VERSION ""

NS_ :

BS_:

BU_: IVS

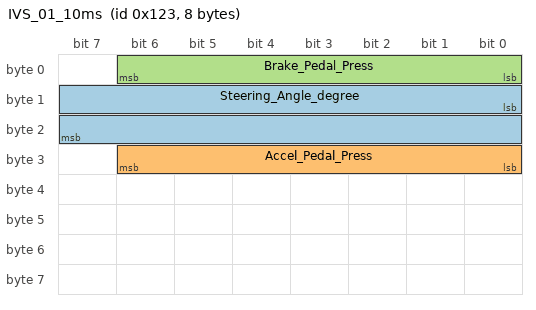
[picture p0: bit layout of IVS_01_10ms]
BO_ 291 IVS_01_10ms: 8 IVS
 SG_ Steering_Angle_degree : 8|16@1- (0.1,0) [0|0] "Deg" Vector__XXX
 SG_ Accel_Pedal_Press : 24|7@1+ (1,0) [0|0] "%" Vector__XXX
 SG_ Brake_Pedal_Press : 0|7@1+ (1,0) [0|0] "%" Vector__XXX
